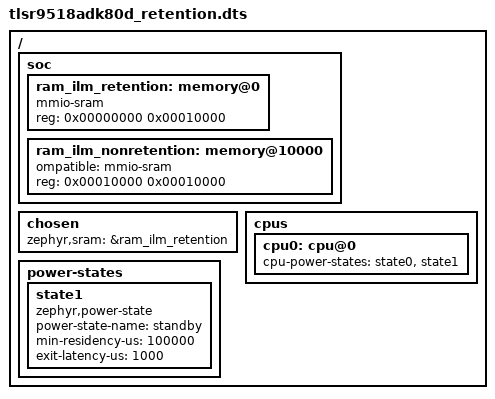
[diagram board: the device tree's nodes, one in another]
/*
 * Copyright (c) 2023-2024 Telink Semiconductor
 *
 * SPDX-License-Identifier: Apache-2.0
 */

/dts-v1/;

#include "tlsr9518adk80d-common.dtsi"

/ {
	soc {

		/delete-node/ memory@0;

		ram_ilm_retention: memory@0 {
			compatible = "mmio-sram";
		};

		ram_ilm_nonretention: memory@10000 {
			ompatible = "mmio-sram";
		};
	};

	chosen {
		zephyr,sram = &ram_ilm_retention;
	};

	cpus {
		cpu0: cpu@0 {
			cpu-power-states = <&state0 &state1>;
		};
	};

	power-states {
		state1: state1 {
			compatible = "zephyr,power-state";
			power-state-name = "standby";
			min-residency-us = <100000>;
			exit-latency-us = <1000>;
		};
	};
};

&ram_ilm_retention {
	reg = <0x00000000 0x00010000>;
};

&ram_ilm_nonretention {
	reg = <0x00010000 0x00010000>;
};
